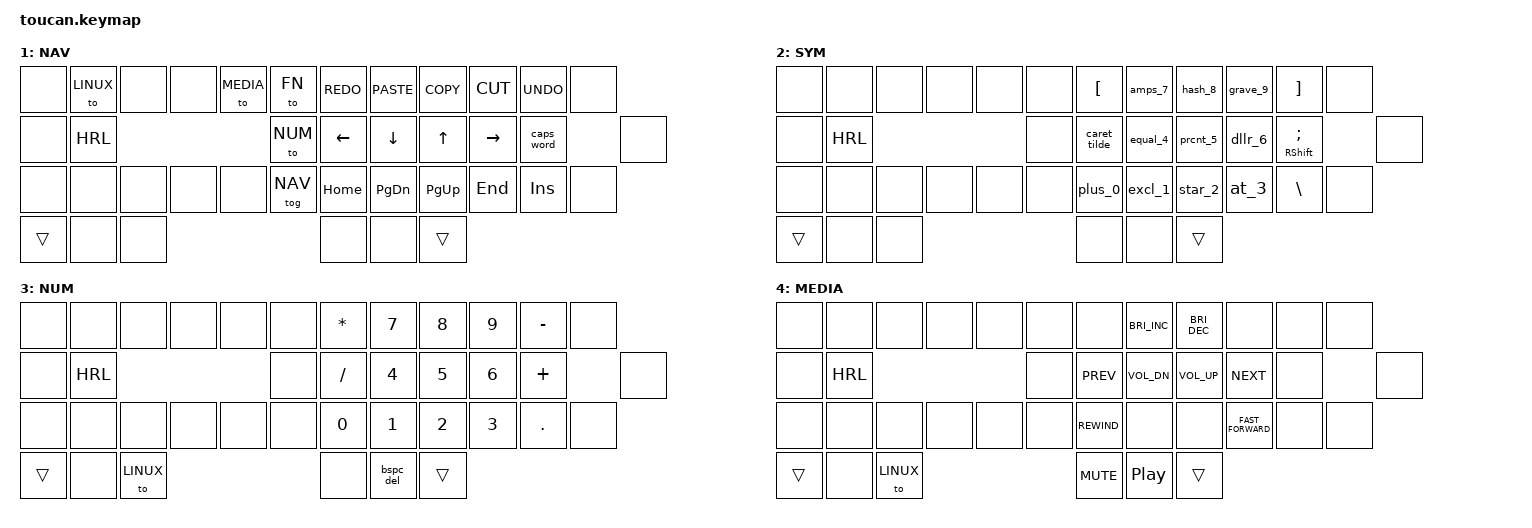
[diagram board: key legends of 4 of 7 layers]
/*
 * Copyright (c) 2020 duckyb
 *
 * SPDX-License-Identifier: MIT
 */

/*  beekeeb Toucan2 (36-key) running the urchin layout from config/urchin.keymap.

    The firmware matrix has 42 positions (3x6+3 per side). The 36-key build has no
    outer pinky column (00/11, 12/23, 24/35), so every row wraps urchin's 10 keys
    in XXX. Urchin's 2 thumbs per side sit on Toucan's middle+inner thumbs. The
    outer thumbs (36, 41) are left click on every layer: tap to click, hold to
    drag. A held outer thumb stays pressed while the finger is lifted and put
    back on the trackpad (ZMK releases a key on the layer it was pressed on).
    The ASCII boxes inside each layer still show urchin's 5 columns.

                              KEY POSITIONS
      ╭─────────────────────────╮       ╭─────────────────────────╮
      │ (00) 01  02  03  04  05 │       │ 06  07  08  09  10 (11) │
      │ (12) 13  14  15  16  17 │       │ 18  19  20  21  22 (23) │
      │ (24) 25  26  27  28  29 │       │ 30  31  32  33  34 (35) │
      ╰───────────╮  36  37  38 │       │ 39  40  41  ╭───────────╯
                  ╰─────────────╯       ╰─────────────╯
      urchin -> toucan:  row0 p+1 | row1 p+3 | row2 p+5 | thumbs 30 31 32 33 -> 37 38 39 40 */


#include <behaviors.dtsi>
#include <dt-bindings/zmk/keys.h>
#include <dt-bindings/zmk/bt.h>
#include <dt-bindings/zmk/outputs.h>
#include <dt-bindings/zmk/pointing.h>

// Layer definitions
#define LINUX   0
#define NAV     1
#define SYM     2
#define NUM     3
#define MEDIA   4
#define FN      5
#define MOUSE   6

#define XXX &none

// -----------------------------------------------------------------------------------------
// define Layer-tap
#define LTS(k1)   &lt SYM k1
#define LTN(k1)   &lt NAV k1
#define LTNUM(k1) &lt NUM k1
#define LTM(k1)   &lt MEDIA k1
#define LTF(k1)   &lt FN k1
// -----------------------------------------------------------------------------------------
// define Home-row modifiers
#define HRML(k1,k2,k3,k4) &kp k1 &ht LCTRL k2 &ht LALT k3 &ht LMETA  k4
#define HRMR(k1,k2,k3,k4) &ht RMETA  k1 &ht RALT  k2 &ht RCTRL  k3 &kp k4
#define HRL &kp LSHIFT &kp LCTRL &kp LALT &kp LMETA
#define HRR &kp RMETA &kp RALT &kp RCTRL &kp RSHIFT


// -----------------------------------------------------------------------------------------

// define Hold-tap properties
#define TAPPING_TERM_MS 175
#define QUICK_TAP_MS 150

// define Combos properties
#define TIMEOUT_MS 40
#define TIMEOUT_MS_SLOW 100

// -----------------------------------------------------------------------------------------
&sk {
    // don't release mods on other mods presses
    ignore-modifiers;
    release-after-ms = <500>;
    quick-release;
};
// -----------------------------------------------------------------------------------------

// define Hold-tap properties
#define TAPPING_TERM_MS 175
#define QUICK_TAP_MS 150

// define Combos properties
#define TIMEOUT_MS 40
#define TIMEOUT_MS_SLOW 100

// -----------------------------------------------------------------------------------------


// -----------------------------------------------------------------------------------------
/ {
// -----------------------------------------------------------------------------------------
        behaviors {
// -----------------------------------------------------------------------------------------
        ht: hold_tap {
            label = "hold_tap";
            compatible = "zmk,behavior-hold-tap";
            #binding-cells = <2>;
            flavor = "tap-preferred";
            tapping-term-ms = <TAPPING_TERM_MS>;
            quick-tap-ms = <QUICK_TAP_MS>;
            global-quick-tap;
            bindings = <&kp>, <&kp>;
        };

// -----------------------------------------------------------------------------------------

        bspc_del: backspace_delete {
            compatible = "zmk,behavior-mod-morph";
            label = "BACKSPACE_DELETE";
            #binding-cells = <0>;
            bindings = <&kp BACKSPACE>, <&kp DELETE>;
            mods = <(MOD_LSFT|MOD_RSFT)>;
            keep-mods = <(MOD_RSFT)>;
        };
        htbd: ht_bspc_del {
            label = "hold_tap_bspc_del";
            compatible = "zmk,behavior-hold-tap";
            #binding-cells = <2>;
            flavor = "tap-preferred";
            tapping-term-ms = <TAPPING_TERM_MS>;
            quick-tap-ms = <QUICK_TAP_MS>;
            global-quick-tap;
            bindings = <&mo>, <&bspc_del>;
        };

        lpar_rpar: lpar_rpar {
            compatible = "zmk,behavior-mod-morph";
            label = "LPAR_RPAR";
            #binding-cells = <0>;
            bindings = <&kp LPAR>, <&kp RPAR>;
            mods = <(MOD_LSFT|MOD_RSFT)>;
            keep-mods = <(MOD_RSFT)>;
        };

        lbrc_rbrc: lbrc_rbrc {
            compatible = "zmk,behavior-mod-morph";
            label = "LBRC_RBRC";
            #binding-cells = <0>;
            bindings = <&kp LBRC>, <&kp RBRC>;
            mods = <(MOD_LSFT|MOD_RSFT)>;
            keep-mods = <(MOD_RSFT)>;
        };

        lbkt_rbkt: lbkt_rbkt {
            compatible = "zmk,behavior-mod-morph";
            label = "LBKT_RBKT";
            #binding-cells = <0>;
            bindings = <&kp LBKT>, <&kp RBKT>;
            mods = <(MOD_LSFT|MOD_RSFT)>;
            keep-mods = <(MOD_RSFT)>;
        };
// -----------------------------------------------------------------------------------------
        htst: ht_space_tab {
            label = "hold_tap_space_tab";
            compatible = "zmk,behavior-hold-tap";
            #binding-cells = <2>;
            flavor = "tap-preferred";
            tapping-term-ms = <TAPPING_TERM_MS>;
            quick-tap-ms = <QUICK_TAP_MS>;
            global-quick-tap;
            bindings = <&mo>, <&space_tab>;
        };
        space_tab: space_tab {
            compatible = "zmk,behavior-mod-morph";
            label = "SPACE_TAB";
            #binding-cells = <0>;
            bindings = <&kp SPACE>, <&kp TAB>;
            mods = <(MOD_LSFT|MOD_RSFT)>;
            keep-mods = <(MOD_RSFT)>;
        };

        htest: ht_esc_stab {
            label = "hold_tap_esc_stab";
            compatible = "zmk,behavior-hold-tap";
            #binding-cells = <2>;
            flavor = "tap-preferred";
            tapping-term-ms = <TAPPING_TERM_MS>;
            quick-tap-ms = <QUICK_TAP_MS>;
            global-quick-tap;
            bindings = <&mo>, <&esc_stab>;
        };
        esc_stab: esc_stab {
            compatible = "zmk,behavior-mod-morph";
            label = "ESC_STAB";
            #binding-cells = <0>;
            bindings = <&kp ESC>, <&kp LS(TAB)>;
            mods = <(MOD_LSFT|MOD_RSFT)>;
            keep-mods = <(MOD_RSFT)>;
        };
    };
// -----------------------------------------------------------------------------------------
// MORPH NUM LAYER
        excl_1: excl_1 {
            compatible = "zmk,behavior-mod-morph";
            label = "EXCL_1";
            #binding-cells = <0>;
            bindings = <&kp EXCL>, <&kp N1>;
            mods = <(MOD_LSFT|MOD_RSFT)>;
            keep-mods = <(MOD_RSFT)>;
        };
        star_2: star_2 {
            compatible = "zmk,behavior-mod-morph";
            label = "STAR_1";
            #binding-cells = <0>;
            bindings = <&kp STAR>, <&kp N2>;
            mods = <(MOD_LSFT|MOD_RSFT)>;
            keep-mods = <(MOD_RSFT)>;
        };
        at_3: at_3 {
            compatible = "zmk,behavior-mod-morph";
            label = "AT_3";
            #binding-cells = <0>;
            bindings = <&kp AT>, <&kp N3>;
            mods = <(MOD_LSFT|MOD_RSFT)>;
            keep-mods = <(MOD_RSFT)>;
        };
        equal_4: equal_4 {
            compatible = "zmk,behavior-mod-morph";
            label = "EQUAL_4";
            #binding-cells = <0>;
            bindings = <&kp EQUAL>, <&kp N4>;
            mods = <(MOD_LSFT|MOD_RSFT)>;
            keep-mods = <(MOD_RSFT)>;
        };
        prcnt_5: prcnt_5 {
            compatible = "zmk,behavior-mod-morph";
            label = "PRCNT_5";
            #binding-cells = <0>;
            bindings = <&kp PRCNT>, <&kp N5>;
            mods = <(MOD_LSFT|MOD_RSFT)>;
            keep-mods = <(MOD_RSFT)>;
        };
        dllr_6: dllr_6 {
            compatible = "zmk,behavior-mod-morph";
            label = "DLLR_6";
            #binding-cells = <0>;
            bindings = <&kp DLLR>, <&kp N6>;
            mods = <(MOD_LSFT|MOD_RSFT)>;
            keep-mods = <(MOD_RSFT)>;
        };
        amps_7: amps_7 {
            compatible = "zmk,behavior-mod-morph";
            label = "AMPS_7";
            #binding-cells = <0>;
            bindings = <&kp AMPS>, <&kp N7>;
            mods = <(MOD_LSFT|MOD_RSFT)>;
            keep-mods = <(MOD_RSFT)>;
        };
        hash_8: hash_8 {
            compatible = "zmk,behavior-mod-morph";
            label = "HASH_8";
            #binding-cells = <0>;
            bindings = <&kp HASH>, <&kp N8>;
            mods = <(MOD_LSFT|MOD_RSFT)>;
            keep-mods = <(MOD_RSFT)>;
        };
        grave_9: grave_9 {
            compatible = "zmk,behavior-mod-morph";
            label = "GRAVE_9";
            #binding-cells = <0>;
            bindings = <&kp GRAVE>, <&kp N9>;
            mods = <(MOD_LSFT|MOD_RSFT)>;
            keep-mods = <(MOD_RSFT)>;
        };
//       lpar_rpar: lpar_rpar {
//           compatible = "zmk,behavior-mod-morph";
//           label = "LPAR_RPAR";
//           #binding-cells = <0>;
//           bindings = <&kp LPAR>, <&kp RPAR>;
//           mods = <(MOD_LSFT|MOD_RSFT)>;
//           keep-mods = <(MOD_RSFT)>;
//       };
        plus_0: plus_0 {
            compatible = "zmk,behavior-mod-morph";
            label = "PLUS_0";
            #binding-cells = <0>;
            bindings = <&kp PLUS>, <&kp N0>;
            mods = <(MOD_LSFT|MOD_RSFT)>;
            keep-mods = <(MOD_RSFT)>;
        };
        caret_tilde: caret_tilde {
            compatible = "zmk,behavior-mod-morph";
            label = "CARET_TILDE";
            #binding-cells = <0>;
            bindings = <&kp CARET>, <&kp TILDE>;
            mods = <(MOD_LSFT|MOD_RSFT)>;
            keep-mods = <(MOD_RSFT)>;
        };


// -----------------------------------------------------------------------------------------
        macros {
// -----------------------------------------------------------------------------------------
        thumb_tap: thumb_tap {
            label = "thumb_tap";
            compatible = "zmk,behavior-macro";
            #binding-cells = <0>;
            bindings
                = <&macro_press &kp TAB>
                , <&macro_tap &kp Z &kp M &kp K>
                , <&macro_release &kp TAB>
                ;
        };

        pscrn_custom: pscrn_custom {
            label = "pscrn_custom";
            compatible = "zmk,behavior-macro";
            #binding-cells = <0>;
            bindings
                = <&kp PSCRN>
                , <&to LINUX>
                ;
        };
    };

// -----------------------------------------------------------------------------------------
        combos {
// -----------------------------------------------------------------------------------------
        compatible = "zmk,combos";

// COMBOS LEFT
        combo_ctlA {
            timeout-ms = <TIMEOUT_MS>;
            key-positions = <13 14>;
            bindings = <&kp LC(A)>;
        };
        combo_esc {
            timeout-ms = <TIMEOUT_MS>;
            key-positions = <2 3>;
            bindings = <&kp ESC>;
        };
//       combo_repeat {
//           timeout-ms = <TIMEOUT_MS>;
//           key-positions = <2 3>;
//           bindings = <&key_repeat>;
//       };
        combo_lshift {
            timeout-ms = <TIMEOUT_MS>;
            key-positions = <14 15>;
            bindings = <&sk LSHIFT>;
        };
        combo_ret {
            timeout-ms = <TIMEOUT_MS>;
            key-positions = <15 16>;
            bindings = <&kp RET>;
        };
        combo_tab {
            timeout-ms = <TIMEOUT_MS>;
            key-positions = <2 3 4>;
            bindings = <&kp TAB>;
        };
//       combo_stab {
//           timeout-ms = <TIMEOUT_MS>;
//           key-positions = <5 6>;
//           bindings = <&kp LS(TAB)>;
//       };
        combo_at { // @
            timeout-ms = <TIMEOUT_MS>;
            key-positions = <2 14>;
            bindings = <&kp AT>;
        };
        combo_grave { // `
            timeout-ms = <TIMEOUT_MS>;
            key-positions = <14 26>;
            bindings = <&kp GRAVE>;
        };
        combo_hash {
            timeout-ms = <TIMEOUT_MS>;
            key-positions = <3 15>;
            bindings = <&kp HASH>;
        };
        combo_bslh {
            timeout-ms = <TIMEOUT_MS>;
            key-positions = <15 27>;
            bindings = <&kp BSLH>;
        };
        combo_amps { // &
            timeout-ms = <TIMEOUT_MS>;
            key-positions = <4 16>;
            bindings = <&kp AMPS>;
        };
        combo_pipe { // |
            timeout-ms = <TIMEOUT_MS>;
            key-positions = <16 28>;
            bindings = <&kp PIPE>;
        };
        combo_prcnt { // %
            timeout-ms = <TIMEOUT_MS>;
            key-positions = <5 17>;
            bindings = <&kp PRCNT>;
        };
        combo_tilde { // ~
            timeout-ms = <TIMEOUT_MS>;
            key-positions = <17 29>;
            bindings = <&kp TILDE>;
        };
//       combo_undo {
//           timeout-ms = <TIMEOUT_MS>;
//           key-positions = <19 20>;
//           bindings = <&kp LC(Z)>;
//       };
//       combo_redo {
//           timeout-ms = <TIMEOUT_MS>;
//           key-positions = <33 34>;
//           bindings = <&kp LC(LS(Z))>;
//       };
//       combo_z {
//           timeout-ms = <TIMEOUT_MS_SLOW>;
//           key-positions = <16 17>;
//           bindings = <&kp Z>;
//       };
        combo_copy {
            timeout-ms = <TIMEOUT_MS>;
            key-positions = <26 27>;
            bindings = <&kp LC(C)>;
        };
        combo_paste {
            timeout-ms = <TIMEOUT_MS>;
            key-positions = <27 28>;
            bindings = <&kp LC(V)>;
        };
        combo_cut {
            timeout-ms = <TIMEOUT_MS>;
            key-positions = <26 28>;
            bindings = <&kp LC(X)>;
        };
//       combo_caps {
//           timeout-ms = <TIMEOUT_MS_SLOW>;
//           key-positions = <19 22>;
//           bindings = <&caps_word>;
//       };

// COMBOS RIGHT
        combo_caret { // ^
            timeout-ms = <TIMEOUT_MS>;
            key-positions = <6 18>;
            bindings = <&kp CARET>;
        };
        combo_under { // _
            timeout-ms = <TIMEOUT_MS>;
            key-positions = <18 30>;
            bindings = <&kp UNDER>;
        };
        combo_plus { // +
            timeout-ms = <TIMEOUT_MS>;
            key-positions = <7 19>;
            bindings = <&kp PLUS>;
        };
        combo_minus { // -
            timeout-ms = <TIMEOUT_MS>;
            key-positions = <19 31>;
            bindings = <&kp MINUS>;
        };
        combo_lbrc {
            timeout-ms = <TIMEOUT_MS>;
            key-positions = <7 8>;
            bindings = <&lbrc_rbrc>;
        };
//       combo_rbrc {
//           timeout-ms = <TIMEOUT_MS>;
//           key-positions = <9 10>;
//           bindings = <&kp RBRC>;
//       };
        combo_lpar {
            timeout-ms = <TIMEOUT_MS>;
            key-positions = <19 20>;
            bindings = <&lpar_rpar>;
        };
        combo_rshift {
            timeout-ms = <TIMEOUT_MS>;
            key-positions = <20 21>;
            bindings = <&sk RSHIFT>;
        };
        combo_lbkt {
            timeout-ms = <TIMEOUT_MS>;
            key-positions = <31 32>;
            bindings = <&lbkt_rbkt>;
        };
//       combo_rbkt {
//           timeout-ms = <TIMEOUT_MS>;
//           key-positions = <39 40>;
//           bindings = <&kp RBKT>;
//       };
        combo_dllr {
            timeout-ms = <TIMEOUT_MS>;
            key-positions = <9 21>;
            bindings = <&kp DLLR>;
        };
        combo_equal {
            timeout-ms = <TIMEOUT_MS>;
            key-positions = <21 33>;
            bindings = <&kp EQUAL>;
        };
        combo_colon {
            timeout-ms = <TIMEOUT_MS>;
            key-positions = <8 9>;
            bindings = <&kp COLON>;
        };
        combo_semi {
            timeout-ms = <TIMEOUT_MS>;
            key-positions = <32 33>;
            bindings = <&kp SEMI>;
        };
        combo_star {
            timeout-ms = <TIMEOUT_MS>;
            key-positions = <8 20>;
            bindings = <&kp STAR>;
        };
        combo_fslh {
            timeout-ms = <TIMEOUT_MS>;
            key-positions = <20 32>;
            bindings = <&kp FSLH>;
        };
        combo_qmark {
            timeout-ms = <TIMEOUT_MS>;
            key-positions = <9 10>;
            bindings = <&kp QMARK>;
        };
        combo_excl {
            timeout-ms = <TIMEOUT_MS>;
            key-positions = <6 7>;
            bindings = <&kp EXCL>;
        };
        combo_to_nav {
            timeout-ms = <TIMEOUT_MS>;
            key-positions = <39 40>;
            bindings = <&to NAV>;
        };
        // Escape hatch: if the trackpad's finger-up is lost, MOUSE stays on and
        // every thumb is a click. Both middle thumbs together go back to base.
        // Only while MOUSE is the top layer, so typing Space+Bksp never fires it.
        combo_exit_mouse {
            timeout-ms = <TIMEOUT_MS_SLOW>;
            key-positions = <37 40>;
            layers = <MOUSE>;
            bindings = <&to LINUX>;
        };
    };
// -----------------------------------------------------------------------------------------
        keymap {
                compatible = "zmk,keymap";

// -----------------------------------------------------------------------------------------
                linux_layer {
// -----------------------------------------------------------------------------------------
                        label = "LINUX";
                        bindings = <
//   ╭──────────┬──────────┬──────────┬──────────┬──────────╮   ╭──────────┬──────────┬──────────┬──────────┬──────────╮
//   │  Q       │  W       │  E       │  R       │  T       │   │  Y       │  U       │  I       │  O       │  P       │
XXX        &kp Q      &kp W      &kp E      &kp R      &kp T          &kp Y      &kp U      &kp I      &kp O      &kp P  XXX
//   ├──────────┼──────────┼──────────┼──────────┼──────────┤   ├──────────┼──────────┼──────────┼──────────┼──────────┤
//   │  A       │  S       │  D       │  F       │  G       │   │  H       │  J       │  K       │  L       │  ' "     │
XXX       HRML(A,      S,         D,         F)         &kp G         &kp H      HRMR(J,     K,         L,         APOS)  XXX
//   ├──────────┼──────────┼──────────┼──────────┼──────────┤   ├──────────┼──────────┼──────────┼──────────┼──────────┤
//   │  Z       │  X       │  C       │  V       │  B       │   │  N       │  M       │  , <     │  . >     │  CAPS    │
XXX        &kp Z      &kp X      &kp C      &kp V      &kp B          &kp N      &kp M      &kp COMMA  &kp DOT   &caps_word  XXX
//   ╰──────────┴──────────┴──────────┴──────────┴──────────╯   ╰──────────┴──────────┴──────────┴──────────┴──────────╯
//                               ╭─────────────┬────────────╮   ╭─────────────┬─────────────╮
//                               │ SPACE/NUM   │  NAV       │   │    X        │      X      │
&mkp LCLK                              LTNUM(SPACE)   &mo NAV           XXX         &bspc_del  &mkp LCLK
//                               ╰─────────────┴────────────╯   ╰─────────────┴─────────────╯
                     >;
             };

// --------------------------------------------------------------------------------------
             nav_layer {
// --------------------------------------------------------------------------------------
                     label = "NAV";
                     bindings = <
//   ╭──────────┬──────────┬──────────┬──────────┬──────────╮   ╭──────────┬──────────┬──────────┬──────────┬──────────╮
//   │  BASE    │   X      │   X      │  MEDIA   │  FN      │   │  REDO    │  PASTE   │  COPY    │  CUT     │  UNDO    │
XXX        &to LINUX   XXX        XXX       &to MEDIA  &to FN        &kp K_REDO &kp K_PASTE &kp K_COPY &kp K_CUT &kp K_UNDO  XXX
//   ├──────────┼──────────┼──────────┼──────────┼──────────┤   ├──────────┼──────────┼──────────┼──────────┼──────────┤
//   │  LSHIFT  │  LCTRL   │  LALT    │  LMETA   │  NUM     │   │  LEFT    │  DOWN    │    UP    │  RIGHT   │  CAPS    │
XXX          HRL                                       &to  NUM        &kp LEFT    &kp DOWN    &kp UP    &kp RIGHT &caps_word  XXX
//   ├──────────┼──────────┼──────────┼──────────┼──────────┤   ├──────────┼──────────┼──────────┼──────────┼──────────┤
//   │  X       │  X       │  X       │  X       │    X     │   │  HOME    │  PG_DN   │  PG_UP   │  END     │  INS     │
XXX        XXX         XXX        XXX        XXX      &tog  NAV       &kp HOME   &kp PG_DN  &kp PG_UP   &kp END    &kp INS  XXX
//   ╰──────────┴──────────┴──────────┴──────────┴──────────╯   ╰──────────┴──────────┴──────────┴──────────┴──────────╯
//                                ╭─────────────┬────────────╮   ╭─────────────┬─────────────╮
//                                │      X      │      X     │   │     X       │     X       │
&trans                                     XXX           XXX             XXX           XXX  &trans
//                                ╰─────────────┴────────────╯   ╰─────────────┴─────────────╯
                        >;
                };

// --------------------------------------------------------------------------------------
             sym_layer {
// --------------------------------------------------------------------------------------
                     label = "SYM";
                     bindings = <
//   ╭──────────┬──────────┬──────────┬──────────┬──────────╮   ╭──────────┬──────────┬──────────┬──────────┬──────────╮
//   │  X       │  X       │  X       │  X       │  X       │   │   [ {    │   & 7    │   # 8    │   ` 9    │   ] }    │
XXX        XXX         XXX        XXX        XXX        XXX          &kp LBKT    &amps_7     &hash_8   &grave_9   &kp RBKT  XXX
//   ├──────────┼──────────┼──────────┼──────────┼──────────┤   ├──────────┼──────────┼──────────┼──────────┼──────────┤
//   │  LSHIFT  │  LCTRL   │  LALT    │  LMETA   │  X       │   │   ^ ~    │   = 4    │   % 5    │   6 $    │  ; :     │
XXX          HRL                                        XXX         &caret_tilde  &equal_4   &prcnt_5   &dllr_6  &ht RSHIFT SEMI  XXX
//   ├──────────┼──────────┼──────────┼──────────┼──────────┤   ├──────────┼──────────┼──────────┼──────────┼──────────┤
//   │  X       │  X       │  X       │  X       │  X       │   │    + 0   │   ! 1    │   * 2    │   @ 3    │   \ |    │
XXX        XXX         XXX        XXX        XXX        XXX            &plus_0    &excl_1   &star_2     &at_3     &kp BSLH  XXX
//   ╰──────────┴──────────┴──────────┴──────────┴──────────╯   ╰──────────┴──────────┴──────────┴──────────┴──────────╯
//                               ╭─────────────┬────────────╮   ╭─────────────┬─────────────╮
//                               │      X      │     X      │   │     X       │      X      │
&trans                                     XXX         XXX              XXX           XXX  &trans
//                               ╰─────────────┴────────────╯   ╰─────────────┴─────────────╯
                     >;
             };
// --------------------------------------------------------------------------------------
             num_layer {
// --------------------------------------------------------------------------------------
                     label = "NUM";
                     bindings = <
//   ╭──────────┬──────────┬──────────┬──────────┬──────────╮   ╭──────────┬──────────┬──────────┬──────────┬──────────╮
//   │  X       │  X       │  X       │  X       │  X       │   │     *    │    7     │     8    │     9    │    -     │
XXX        XXX         XXX        XXX        XXX        XXX           &kp STAR    &kp N7     &kp N8     &kp N9    &kp MINUS  XXX
//   ├──────────┼──────────┼──────────┼──────────┼──────────┤   ├──────────┼──────────┼──────────┼──────────┼──────────┤
//   │  LSHIFT  │  LCTRL   │  LALT    │  LMETA   │  X       │   │     /    │    4     │     5    │     6    │    +     │
XXX          HRL                                        XXX           &kp SLASH   &kp N4      &kp N5    &kp N6     &kp PLUS  XXX
//   ├──────────┼──────────┼──────────┼──────────┼──────────┤   ├──────────┼──────────┼──────────┼──────────┼──────────┤
//   │  X       │  X       │  X       │  X       │  X       │   │     0    │    1     │     2    │     3    │    .     │
XXX        XXX         XXX        XXX        XXX        XXX           &kp N0      &kp N1     &kp N2     &kp N3    &kp DOT  XXX
//   ╰──────────┴──────────┴──────────┴──────────┴──────────╯   ╰──────────┴──────────┴──────────┴──────────┴──────────╯
//                               ╭─────────────┬────────────╮   ╭─────────────┬─────────────╮
//                               │      X      │    NAV     │   │     X       │      X      │
&trans                                     XXX        &to LINUX          XXX        &bspc_del  &trans
//                               ╰─────────────┴────────────╯   ╰─────────────┴─────────────╯
                     >;
             };

// --------------------------------------------------------------------------------------
             media_layer {
// --------------------------------------------------------------------------------------
                     label = "MEDIA";
                     bindings = <
//   ╭──────────┬──────────┬──────────┬──────────┬──────────╮   ╭─────────────────┬──────────────────────┬─────────────────────┬────────────────┬────────────────╮
//   │  X       │  X       │  X       │  X       │  X       │   │       X         │          BRI_UP      │        BRI_DN       │       X        │      X         │
XXX        XXX         XXX        XXX        XXX        XXX                XXX          &kp C_BRIGHTNESS_INC   &kp C_BRIGHTNESS_DEC       XXX             XXX  XXX
//   ├──────────┼──────────┼──────────┼──────────┼──────────┤   ├─────────────────┼──────────────────────┼─────────────────────┼────────────────┼────────────────┤
//   │  X       │  X       │  X       │  X       │  X       │   │      Prev       │       Vol down       │        Vol up       │      Next      │      X         │
XXX        HRL                                          XXX              &kp C_PREV         &kp C_VOL_DN           &kp C_VOL_UP        &kp C_NEXT         XXX  XXX
//   ├──────────┼──────────┼──────────┼──────────┼──────────┤   ├─────────────────┼──────────────────────┼─────────────────────┼────────────────┼────────────────┤
//   │  X       │  X       │  X       │  X       │  X       │   │     REWIND      │           X          │           X         │      FFWD      │      X         │
XXX        XXX         XXX        XXX        XXX        XXX             &kp C_REWIND             XXX                    XXX         &kp C_FAST_FORWARD    XXX  XXX
//   ╰──────────┴──────────┴──────────┴──────────┴──────────╯   ╰─────────────────┴──────────────────────┴─────────────────────┴────────────────┴────────────────╯
//                               ╭─────────────┬────────────╮   ╭────────────┬─────────────╮
//                               │    X        │    NAV     │   │  Mute      │  Play/Pause │
&trans                                   XXX         &to LINUX        &kp C_MUTE     &kp C_PP  &trans
//                               ╰─────────────┴────────────╯   ╰─────────────┴────────────╯
                     >;
             };

// --------------------------------------------------------------------------------------
             fn_layer {
// --------------------------------------------------------------------------------------
                     // Middle thumbs: bootloader for the half they sit on (ZMK runs
                     // &bootloader on the pressing half). Flash the right half first:
                     // once the left half is in its bootloader the right is unreachable.
                     label = "FN";
                     bindings = <
//   ╭──────────┬──────────┬──────────┬──────────┬──────────╮   ╭──────────────┬─────────────┬──────────────┬──────────────┬──────────────╮
//   │   F12    │    F7    │    F8    │    F9    │  PSCRN   │   │    BT_PRV    │   BT_PRV    │    BT_NXT    │   BT_NXT     │   BT_CLR     │
XXX        &kp F12    &kp F7     &kp F8     &kp F9   &pscrn_custom     &bt BT_PRV    &bt BT_PRV     &bt BT_NXT     &bt BT_NXT     &bt BT_CLR  XXX
//   ├──────────┼──────────┼──────────┼──────────┼──────────┤   ├──────────────┼─────────────┼──────────────┼──────────────┼──────────────┤
//   │   F11    │    F4    │    F5    │    F6    │  NUMLOCK │   │   BEHAVIOR   │    RMETA    │    RALT      │     RCTRL    │   RSHIFT     │
XXX        &kp F11    &kp F4     &kp F5     &kp F6   &kp KP_NLCK      &out OUT_TOG    &kp RMETA      &kp RALT      &kp RCTRL     &kp RSHIFT  XXX
//   ├──────────┼──────────┼──────────┼──────────┼──────────┤   ├──────────────┼─────────────┼──────────────┼──────────────┼──────────────┤
//   │   F10    │    F1    │    F2    │    F3    │  BREAK   │   │   BT_SEL 1   │  BT_SEL 2   │   BT_SEL 3   │   BT_SEL 4   │   BT_SEL 5   │
XXX        &kp F10    &kp F1     &kp F2     &kp F3  &kp PAUSE_BREAK   &bt BT_SEL 0   &bt BT_SEL 1   &bt BT_SEL 2  &bt BT_SEL 3    &bt BT_SEL 4  XXX
//   ╰──────────┴──────────┴──────────┴──────────┴──────────╯   ╰──────────────┴─────────────┴──────────────┴──────────────┴──────────────╯
//                               ╭─────────────┬────────────╮   ╭─────────────┬─────────────╮
//                               │ BOOTLOADER  │    NAV     │   │     X       │ BOOTLOADER  │
&trans                               &bootloader       &to LINUX         XXX       &bootloader  &trans
//                               ╰─────────────┴────────────╯   ╰─────────────┴─────────────╯
                     >;
             };

// --------------------------------------------------------------------------------------
             mouse_layer {
// --------------------------------------------------------------------------------------
                     // Held by the trackpad while it is touched (is_touching_processor
                     // below). Thumbs read like a mouse on both sides:
                     // outer = left, middle = middle, inner = right.
                     label = "MOUSE";
                     bindings = <
       &trans &trans &trans &trans &trans &trans    &trans &trans &trans &trans &trans &trans
       &trans &trans &trans &trans &trans &trans    &trans &trans &trans &trans &trans &trans
       &trans &trans &trans &trans &trans &trans    &trans &trans &trans &trans &trans &trans
                      &mkp LCLK &mkp MCLK &mkp RCLK    &mkp RCLK &mkp MCLK &mkp LCLK
                     >;
             };

// -----------------------------------------------------------------------------------------
        };
};

// -----------------------------------------------------------------------------------------
// Toucan2 trackpad (nodes from beekeeb's toucan.dtsi)
// Stock binds touch to layer 4, which is MEDIA here.
&is_touching_processor {
    bindings = <&mo MOUSE>;
};

// Pinch zoom: Ctrl -/= (stock sends Cmd -/= for macOS).
&zip_zoom_mapper {
    bindings = <&kp LC(MINUS)>, <&kp LC(EQUAL)>;
};

// Three-finger swipes, like this Mac's own trackpad (OmniWM scrolls columns with
// three fingers; four fingers up/down are Mission Control / App Exposé there).
// One shortcut per swipe; the column follows the fingers, as on a MacBook.
// codes order (toucan.dtsi): NORTH (up), EAST (right), SOUTH (down), WEST (left)
&swipe_button_mapper {
    bindings = <&kp LC(UP)>,     // up: Mission Control
               <&kp LA(LEFT)>,   // right: OmniWM focus.left
               <&kp LC(DOWN)>,   // down: App Exposé (application windows)
               <&kp LA(RIGHT)>;  // left: OmniWM focus.right
};
